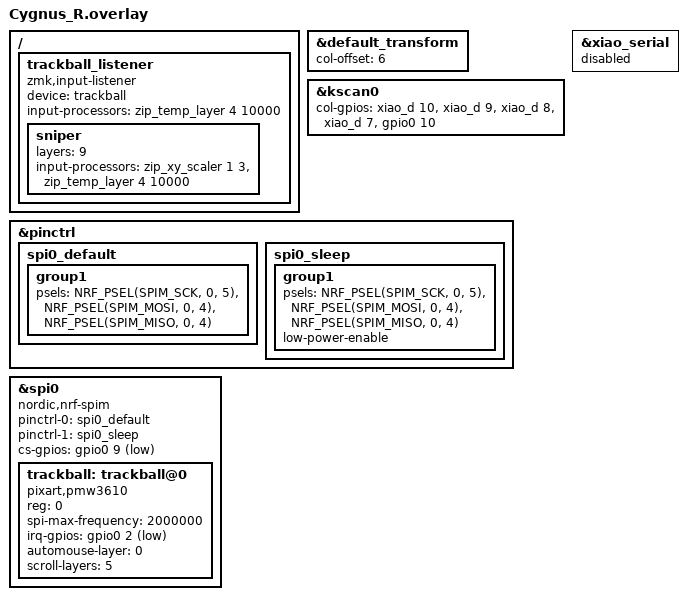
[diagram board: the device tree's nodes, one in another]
#include "Cygnus.dtsi"
/* 💡追加：スナイパー機能（scaler）の設計図を読み込む */
#include <input/processors.dtsi>

&default_transform {
    col-offset = <6>;
};

&kscan0 {
    col-gpios
        = <&xiao_d 10 GPIO_ACTIVE_HIGH>
        , <&xiao_d 9 GPIO_ACTIVE_HIGH>
        , <&xiao_d 8 GPIO_ACTIVE_HIGH>
        , <&xiao_d 7 GPIO_ACTIVE_HIGH>
        , <&gpio0 10 GPIO_ACTIVE_HIGH>
        ;
};

/ {
    /* ─── 2. トラックボールのリスナー（AMLを呼び出す） ─── */
    trackball_listener {
        compatible = "zmk,input-listener";
        device = <&trackball>;
        
        /* 💡変更：スナイパーレイヤー（9）がアクティブな時の専用処理 */
        /* 移動量を 1/3 に間引き（減速）しつつ、マウスレイヤーにも移行させる */
        sniper {
            layers = <9>;
            input-processors = <&zip_xy_scaler 1 3>, <&zip_temp_layer 4 10000>;
        };

        /* デフォルト：トラックボール検知後、10秒間レイヤー4（MOUSE）を維持 */
        input-processors = <&zip_temp_layer 4 10000>;
    };
};

/* ─── 3. ピン設定とデバイス定義（必須の心臓部） ─── */
&pinctrl {
    spi0_default: spi0_default {
        group1 {
            psels = <NRF_PSEL(SPIM_SCK, 0, 5)>,
                    <NRF_PSEL(SPIM_MOSI, 0, 4)>,
                    <NRF_PSEL(SPIM_MISO, 0, 4)>;
        };
    };
    spi0_sleep: spi0_sleep {
        group1 {
            psels = <NRF_PSEL(SPIM_SCK, 0, 5)>,
                    <NRF_PSEL(SPIM_MOSI, 0, 4)>,
                    <NRF_PSEL(SPIM_MISO, 0, 4)>;
            low-power-enable;
        };
    };
};

&xiao_serial { status = "disabled"; };

&spi0 {
    status = "okay";
    compatible = "nordic,nrf-spim";
    pinctrl-0 = <&spi0_default>;
    pinctrl-1 = <&spi0_sleep>;
    pinctrl-names = "default", "sleep";
    cs-gpios = <&gpio0 9 GPIO_ACTIVE_LOW>;
    
    trackball: trackball@0 {
        status = "okay";
        compatible = "pixart,pmw3610";
        reg = <0>;
        spi-max-frequency = <2000000>;
        irq-gpios = <&gpio0 2 (GPIO_ACTIVE_LOW | GPIO_PULL_UP)>;
        automouse-layer = <0>;
        scroll-layers = <5>;
    };
};
